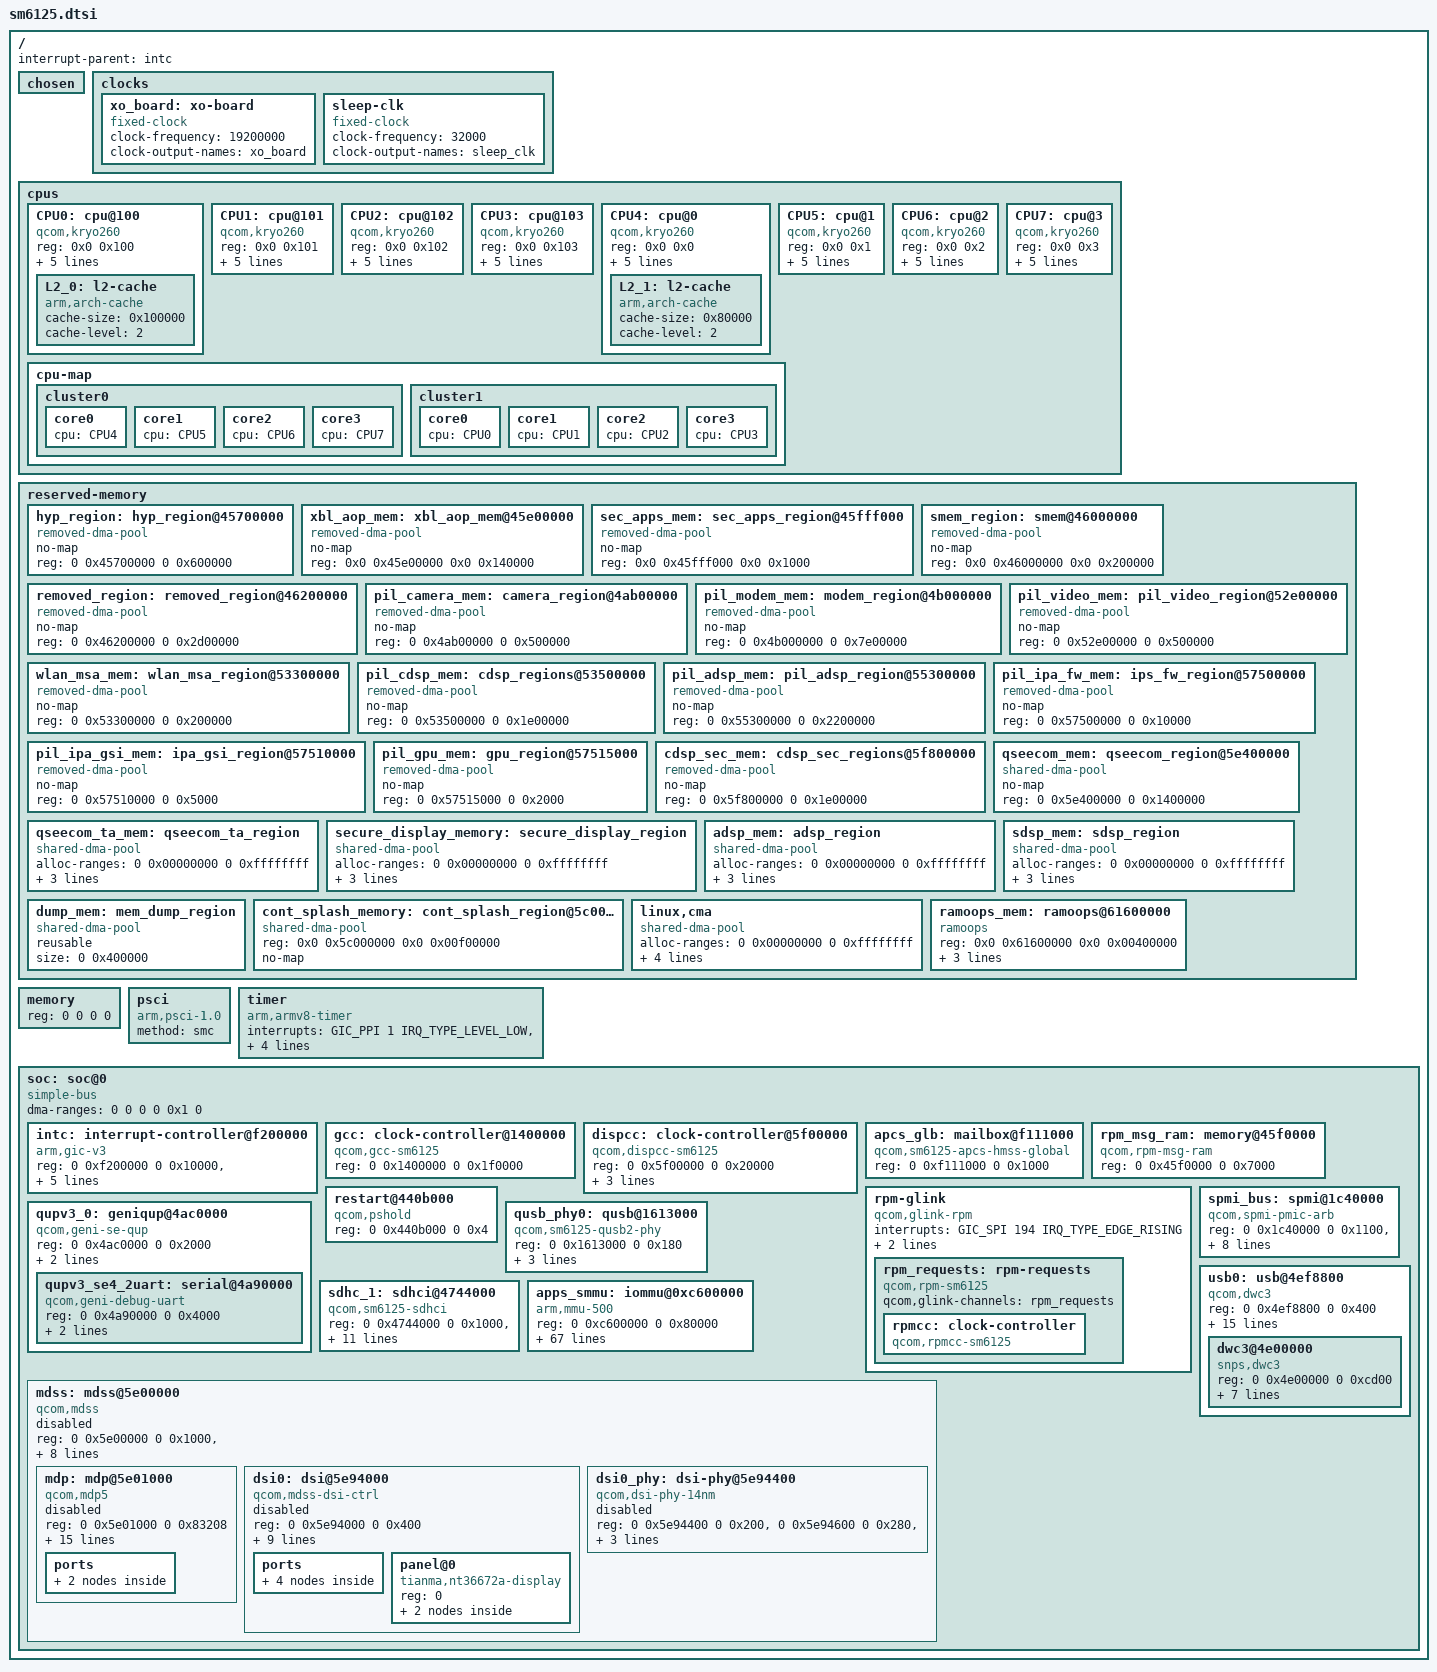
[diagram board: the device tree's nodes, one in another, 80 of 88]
// SPDX-License-Identifier: GPL-2.0-only
// Copyright (c) 2018-2019, The Linux Foundation. All rights reserved.
// Copyright (C) 2019 XiaoMi, Inc.
// Copyright (C) 2020 Eli Riggs <eli@rje.li>

#include <dt-bindings/interrupt-controller/arm-gic.h>
#include <dt-bindings/clock/qcom,gcc-sm6125.h>
#include <dt-bindings/clock/qcom,dispcc-sm6125.h>
#include <dt-bindings/clock/qcom,rpmcc.h>

/ {
	interrupt-parent = <&intc>;

	#address-cells = <2>;
	#size-cells = <2>;

	chosen { };

	clocks {
		xo_board: xo-board {
			compatible = "fixed-clock";
			#clock-cells = <0>;
			clock-frequency = <19200000>;
			clock-output-names = "xo_board";
		};
		sleep-clk {
			compatible = "fixed-clock";
			#clock-cells = <0>;
			clock-frequency = <32000>;
			clock-output-names = "sleep_clk";
		};
	};

	cpus {
		#address-cells = <2>;
		#size-cells = <0>;
		CPU0: cpu@100 {
			device_type = "cpu";
			compatible = "qcom,kryo260";
			reg = <0x0 0x100>;
			enable-method = "psci";
			capacity-dmips-mhz = <1638>;
			d-cache-size = <0x10000>;
			i-cache-size = <0x10000>;
			next-level-cache = <&L2_0>;
			#cooling-cells = <2>;
			L2_0: l2-cache {
				compatible = "arm,arch-cache";
				cache-size = <0x100000>;
				cache-level = <2>;
			};
		};
		CPU1: cpu@101 {
			device_type = "cpu";
			compatible = "qcom,kryo260";
			reg = <0x0 0x101>;
			enable-method = "psci";
			capacity-dmips-mhz = <1638>;
			d-cache-size = <0x10000>;
			i-cache-size = <0x10000>;
			next-level-cache = <&L2_0>;
			#cooling-cells = <2>;
		};
		CPU2: cpu@102 {
			device_type = "cpu";
			compatible = "qcom,kryo260";
			reg = <0x0 0x102>;
			enable-method = "psci";
			capacity-dmips-mhz = <1638>;
			d-cache-size = <0x10000>;
			i-cache-size = <0x10000>;
			next-level-cache = <&L2_0>;
			#cooling-cells = <2>;
		};
		CPU3: cpu@103 {
			device_type = "cpu";
			compatible = "qcom,kryo260";
			reg = <0x0 0x103>;
			enable-method = "psci";
			capacity-dmips-mhz = <1638>;
			d-cache-size = <0x10000>;
			i-cache-size = <0x10000>;
			next-level-cache = <&L2_0>;
			#cooling-cells = <2>;
		};
		CPU4: cpu@0 {
			device_type = "cpu";
			compatible = "qcom,kryo260";
			reg = <0x0 0x0>;
			enable-method = "psci";
			capacity-dmips-mhz = <1024>;
			d-cache-size = <0x8000>;
			i-cache-size = <0x8000>;
			next-level-cache = <&L2_1>;
			#cooling-cells = <2>;
			L2_1: l2-cache {
				compatible = "arm,arch-cache";
				cache-size = <0x80000>;
				cache-level = <2>;
			};
		};
		CPU5: cpu@1 {
			device_type = "cpu";
			compatible = "qcom,kryo260";
			reg = <0x0 0x1>;
			enable-method = "psci";
			capacity-dmips-mhz = <1024>;
			d-cache-size = <0x8000>;
			i-cache-size = <0x8000>;
			next-level-cache = <&L2_1>;
			#cooling-cells = <2>;
		};
		CPU6: cpu@2 {
			device_type = "cpu";
			compatible = "qcom,kryo260";
			reg = <0x0 0x2>;
			enable-method = "psci";
			capacity-dmips-mhz = <1024>;
			d-cache-size = <0x8000>;
			i-cache-size = <0x8000>;
			next-level-cache = <&L2_1>;
			#cooling-cells = <2>;
		};
		CPU7: cpu@3 {
			device_type = "cpu";
			compatible = "qcom,kryo260";
			reg = <0x0 0x3>;
			enable-method = "psci";
			capacity-dmips-mhz = <1024>;
			d-cache-size = <0x8000>;
			i-cache-size = <0x8000>;
			next-level-cache = <&L2_1>;
			#cooling-cells = <2>;
		};
		cpu-map {
			cluster0 {
				core0 {
					cpu = <&CPU4>;
				};
				core1 {
					cpu = <&CPU5>;
				};
				core2 {
					cpu = <&CPU6>;
				};
				core3 {
					cpu = <&CPU7>;
				};
			};
			cluster1 {
				core0 {
					cpu = <&CPU0>;
				};
				core1 {
					cpu = <&CPU1>;
				};
				core2 {
					cpu = <&CPU2>;
				};
				core3 {
					cpu = <&CPU3>;
				};
			};
		};
	};

	reserved-memory {
		#address-cells = <2>;
		#size-cells = <2>;
		ranges;

		hyp_region: hyp_region@45700000 {
			compatible = "removed-dma-pool";
			no-map;
			reg = <0 0x45700000 0 0x600000>;
		};

		xbl_aop_mem: xbl_aop_mem@45e00000 {
			compatible = "removed-dma-pool";
			no-map;
			reg = <0x0 0x45e00000 0x0 0x140000>;
		};

		sec_apps_mem: sec_apps_region@45fff000 {
			compatible = "removed-dma-pool";
			no-map;
			reg = <0x0 0x45fff000 0x0 0x1000>;
		};

		smem_region: smem@46000000 {
			compatible = "removed-dma-pool";
			no-map;
			reg = <0x0 0x46000000 0x0 0x200000>;
		};

		removed_region: removed_region@46200000 {
			compatible = "removed-dma-pool";
			no-map;
			reg = <0 0x46200000 0 0x2d00000>;
		};

		pil_camera_mem: camera_region@4ab00000 {
			compatible = "removed-dma-pool";
			no-map;
			reg = <0 0x4ab00000 0 0x500000>;
		};

		pil_modem_mem: modem_region@4b000000 {
			compatible = "removed-dma-pool";
			no-map;
			reg = <0 0x4b000000 0 0x7e00000>;
		};

		pil_video_mem: pil_video_region@52e00000 {
			compatible = "removed-dma-pool";
			no-map;
			reg = <0 0x52e00000 0 0x500000>;
		};

		wlan_msa_mem: wlan_msa_region@53300000 {
			compatible = "removed-dma-pool";
			no-map;
			reg = <0 0x53300000 0 0x200000>;
		};

		pil_cdsp_mem: cdsp_regions@53500000 {
			compatible = "removed-dma-pool";
			no-map;
			reg = <0 0x53500000 0 0x1e00000>;
		};

		pil_adsp_mem: pil_adsp_region@55300000 {
			compatible = "removed-dma-pool";
			no-map;
			reg = <0 0x55300000 0 0x2200000>;
		};

		pil_ipa_fw_mem: ips_fw_region@57500000 {
			compatible = "removed-dma-pool";
			no-map;
			reg = <0 0x57500000 0 0x10000>;
		};

		pil_ipa_gsi_mem: ipa_gsi_region@57510000 {
			compatible = "removed-dma-pool";
			no-map;
			reg = <0 0x57510000 0 0x5000>;
		};

		pil_gpu_mem: gpu_region@57515000 {
			compatible = "removed-dma-pool";
			no-map;
			reg = <0 0x57515000 0 0x2000>;
		};

		cdsp_sec_mem: cdsp_sec_regions@5f800000 {
			compatible = "removed-dma-pool";
			no-map;
			reg = <0 0x5f800000 0 0x1e00000>;
		};

		qseecom_mem: qseecom_region@5e400000 {
			compatible = "shared-dma-pool";
			no-map;
			reg = <0 0x5e400000 0 0x1400000>;
		};

		qseecom_ta_mem: qseecom_ta_region {
			compatible = "shared-dma-pool";
			alloc-ranges = <0 0x00000000 0 0xffffffff>;
			reusable;
			alignment = <0 0x400000>;
			size = <0 0x1000000>;
		};

		secure_display_memory: secure_display_region {
			compatible = "shared-dma-pool";
			alloc-ranges = <0 0x00000000 0 0xffffffff>;
			reusable;
			alignment = <0 0x400000>;
			size = <0 0x8c00000>;
		};

		adsp_mem: adsp_region {
			compatible = "shared-dma-pool";
			alloc-ranges = <0 0x00000000 0 0xffffffff>;
			reusable;
			alignment = <0 0x400000>;
			size = <0 0x800000>;
		};

		sdsp_mem: sdsp_region {
			compatible = "shared-dma-pool";
			alloc-ranges = <0 0x00000000 0 0xffffffff>;
			reusable;
			alignment = <0 0x400000>;
			size = <0 0x400000>;
		};

		dump_mem: mem_dump_region {
			compatible = "shared-dma-pool";
			reusable;
			size = <0 0x400000>;
		};


		cont_splash_memory: cont_splash_region@5c000000 {
			// reg = <0x0 0x5c000000 0x0 0x00f00000>;
			// label = "cont_splash_region";
			compatible = "shared-dma-pool";
			reg = <0x0 0x5c000000 0x0 0x00f00000>;
			no-map;
		};

		/*
		dfps_data_memory: dfps_data_region@5cf00000 {
			reg = <0x0 0x5cf00000 0x0 0x0100000>;
			label = "dfps_data_region";
		};
		*/

		/*
		disp_rdump_memory: disp_rdump_region@5c000000 {
			reg = <0x0 0x5c000000 0x0 0x01000000>;
			label = "disp_rdump_region";
		};
		*/

		/* global autoconfigured region for contiguous allocations */
		linux,cma {
			compatible = "shared-dma-pool";
			alloc-ranges = <0 0x00000000 0 0xffffffff>;
			reusable;
			alignment = <0 0x400000>;
			size = <0 0x2000000>;
			linux,cma-default;
		};

		/* reserve for pstore */
		ramoops_mem: ramoops@61600000 {
			compatible = "ramoops";
			reg = <0x0 0x61600000 0x0 0x00400000>;

			record-size = <0x80000>;
			pmsg-size = <0x200000>;
			console-size = <0x100000>;
		};
	};

	memory {
		device_type = "memory";
		/* We expect the bootloader to fill this in */
		reg = <0 0 0 0>;
	};

	psci {
		compatible = "arm,psci-1.0";
		method = "smc";
	};

	timer {
		compatible = "arm,armv8-timer";
		interrupts = <GIC_PPI 1 IRQ_TYPE_LEVEL_LOW>,
			     <GIC_PPI 2 IRQ_TYPE_LEVEL_LOW>,
			     <GIC_PPI 3 IRQ_TYPE_LEVEL_LOW>,
			     <GIC_PPI 0 IRQ_TYPE_LEVEL_LOW>;
		clock-frequency = <19200000>;
	};

	soc: soc@0 {
		#address-cells = <2>;
		#size-cells = <2>;
		ranges = <0 0 0 0 0x1 0>;
		dma-ranges = <0 0 0 0 0x1 0>;
		compatible = "simple-bus";

		intc: interrupt-controller@f200000 {
			compatible = "arm,gic-v3";
			reg = <0 0xf200000 0 0x10000>,	/* GICD */
			      <0 0xf300000 0 0x100000>;	/* GICR * 8 */
			#interrupt-cells = <3>;
			#address-cells = <2>;
			#size-cells = <2>;
			ranges;
			interrupt-controller;
			#redistributor-regions = <1>;
			redistributor-stride = <0x0 0x20000>;
			interrupts = <GIC_PPI 9 IRQ_TYPE_LEVEL_HIGH>;
		};

		gcc: clock-controller@1400000 {
			compatible = "qcom,gcc-sm6125";
			reg = <0 0x1400000 0 0x1f0000>;
			#clock-cells = <1>;
			#reset-cells = <1>;
			#power-domain-cells = <1>;
		};

		dispcc: clock-controller@5f00000 {
			compatible = "qcom,dispcc-sm6125";
			reg = <0 0x5f00000 0 0x20000>;

			clock-names = "bi_tcxo",
				      "gcc_disp_gpll0_div_clk_src",
				      "dsi0_phy_pll_out_byteclk",
				      "dsi0_phy_pll_out_dsiclk";
			clocks = <&rpmcc RPM_SMD_XO_CLK_SRC>,
				 <&gcc GCC_DISP_GPLL0_DIV_CLK_SRC>,
				 <&dsi0_phy 0>,
				 <&dsi0_phy 1>;

			#clock-cells = <1>;
			#power-domain-cells = <1>;
		};

		apcs_glb: mailbox@f111000 {
			compatible = "qcom,sm6125-apcs-hmss-global";
			reg = <0 0xf111000 0 0x1000>;
			#mbox-cells = <1>;
		};

		rpm_msg_ram: memory@45f0000 {
			compatible = "qcom,rpm-msg-ram";
			reg = <0 0x45f0000 0 0x7000>;
		};

		rpm-glink {
			compatible = "qcom,glink-rpm";
			interrupts = <GIC_SPI 194 IRQ_TYPE_EDGE_RISING>;
			qcom,rpm-msg-ram = <&rpm_msg_ram>;
			mboxes = <&apcs_glb 0>;
			rpm_requests: rpm-requests {
				compatible = "qcom,rpm-sm6125";
				qcom,glink-channels = "rpm_requests";
				rpmcc: clock-controller {
					compatible = "qcom,rpmcc-sm6125", "qcom,rpmcc";
					#clock-cells = <1>;
				};
			};
		};

		restart@440b000 {
			compatible = "qcom,pshold";
			reg = <0 0x440b000 0 0x4>;
		};

		spmi_bus: spmi@1c40000 {
			compatible = "qcom,spmi-pmic-arb";
			reg-names = "core", "chnls", "obsrvr", "intr", "cnfg";
			reg = <0 0x1c40000 0 0x1100>,
			      <0 0x1e00000 0 0x2000000>,
			      <0 0x3e00000 0 0x100000>,
			      <0 0x3f00000 0 0xa0000>,
			      <0 0x1c0a000 0 0x26000>;
			interrupt-names = "periph_irq";
			interrupts = <GIC_SPI 183 IRQ_TYPE_LEVEL_HIGH>;
			qcom,ee = <0>;
			qcom,channel = <0>;
			#address-cells = <2>;
			#size-cells = <0>;
			interrupt-controller;
			#interrupt-cells = <4>;
			cell-index = <0>;
		};

		qupv3_0: geniqup@4ac0000 {
			compatible = "qcom,geni-se-qup";
			reg = <0 0x4ac0000 0 0x2000>;
			clock-names = "m-ahb", "s-ahb";
			clocks = <&gcc GCC_QUPV3_WRAP_0_M_AHB_CLK>,
				 <&gcc GCC_QUPV3_WRAP_0_S_AHB_CLK>;
			#address-cells = <2>;
			#size-cells = <2>;
			ranges;

			qupv3_se4_2uart: serial@4a90000 {
				compatible = "qcom,geni-debug-uart";
				reg = <0 0x4a90000 0 0x4000>;
				interrupts = <GIC_SPI 331 IRQ_TYPE_LEVEL_HIGH>;
				clock-names = "se";
				clocks = <&gcc GCC_QUPV3_WRAP0_S4_CLK>;
			};
		};

		qusb_phy0: qusb@1613000 {
			compatible = "qcom,sm6125-qusb2-phy";
			reg = <0 0x1613000 0 0x180>;
			#phy-cells = <0>;

			clock-names = "cfg_ahb", "ref";
			clocks = <&gcc GCC_AHB2PHY_USB_CLK>,
				 <&rpmcc RPM_SMD_XO_CLK_SRC>;

			/*
			vdda-pll-supply = <&pm6125_l10>;
			vdda-phy-dpdm-supply = <&pm6125_l15>;
			*/

			resets = <&gcc GCC_QUSB2PHY_PRIM_BCR>;
		};

		usb0: usb@4ef8800 {
			compatible = "qcom,dwc3";
			reg = <0 0x4ef8800 0 0x400>;
			#address-cells = <2>;
			#size-cells = <2>;
			ranges;

			interrupt-names = "hs_phy_irq", "ss_phy_irq";
			interrupts = <GIC_SPI 260 IRQ_TYPE_LEVEL_HIGH>,
				     <GIC_SPI 422 IRQ_TYPE_LEVEL_HIGH>;

			clock-names = "core", "mock_utmi", "sleep",
				      "iface", "cfg_noc", "ref";
			clocks = <&gcc GCC_USB30_PRIM_MASTER_CLK>,
				 <&gcc GCC_USB30_PRIM_MOCK_UTMI_CLK>,
				 <&gcc GCC_USB30_PRIM_SLEEP_CLK>,
				 <&gcc GCC_SYS_NOC_USB3_PRIM_AXI_CLK>,
				 <&gcc GCC_CFG_NOC_USB3_PRIM_AXI_CLK>,
				 <&gcc GCC_USB3_PRIM_CLKREF_CLK>;

			assigned-clocks = <&gcc GCC_USB30_PRIM_MOCK_UTMI_CLK>,
					  <&gcc GCC_USB30_PRIM_MASTER_CLK>;
			assigned-clock-rates = <19200000>, <66666667>;

			reset-names = "core_reset";
			resets = <&gcc GCC_USB30_PRIM_BCR>;
			power-domains = <&gcc USB30_PRIM_GDSC>;

			qcom,select-utmi-as-pipe-clk;

			dwc3@4e00000 {
				compatible = "snps,dwc3";
				reg = <0 0x4e00000 0 0xcd00>;
				interrupts = <GIC_SPI 255 IRQ_TYPE_LEVEL_HIGH>;
				phy-names = "usb2-phy";
				phys = <&qusb_phy0>;
				snps,has-lpm-erratum;
				snps,hird-threshold = /bits/ 8 <0x10>;
				snps,usb3_lpm_capable;
				maximum-speed = "high-speed";
				dr_mode = "peripheral";
			};
		};

		sdhc_1: sdhci@4744000 {
			compatible = "qcom,sm6125-sdhci", "qcom,sdhci-msm-v5";
			reg-names = "hc", "cqhci";
			reg = <0 0x4744000 0 0x1000>,
			      <0 0x4745000 0 0x1000>;

			interrupt-names = "hc_irq", "pwr_irq";
			interrupts = <GIC_SPI 348 IRQ_TYPE_LEVEL_HIGH>,
				     <GIC_SPI 352 IRQ_TYPE_LEVEL_HIGH>;

			clock-names = "iface", "core";
			clocks = <&gcc GCC_SDCC1_AHB_CLK>,
				 <&gcc GCC_SDCC1_APPS_CLK>;

			bus-width = <8>;
			non-removable;
			supports-cqe;

			mmc-ddr-1_8v;
			mmc-hs200-1_8v;
			mmc-hs400-1_8v;
		};

		/*
		tlmm: pinctrl@400000 {
			compatible = "qcom,sm6125-pinctrl";
			reg = <0 0x400000 0 0xc00000>;
			interrupts = <GIC_SPI 227 IRQ_TYPE_LEVEL_HIGH>;
			gpio-controller;
			#gpio-cells = <2>;
			interrupt-controller;
			#interrupt-cells = <2>;
		};
		*/

		apps_smmu: iommu@0xc600000 {
			compatible = "arm,mmu-500";
			reg = <0 0xc600000 0 0x80000>;
			// status = "disabled";
			qcom,skip-init;
			#iommu-cells = <2>;
			#global-interrupts = <1>;
			interrupts =	<GIC_SPI 81 IRQ_TYPE_LEVEL_HIGH>,
					<GIC_SPI 88 IRQ_TYPE_LEVEL_HIGH>,
					<GIC_SPI 89 IRQ_TYPE_LEVEL_HIGH>,
					<GIC_SPI 90 IRQ_TYPE_LEVEL_HIGH>,
					<GIC_SPI 91 IRQ_TYPE_LEVEL_HIGH>,
					<GIC_SPI 92 IRQ_TYPE_LEVEL_HIGH>,
					<GIC_SPI 93 IRQ_TYPE_LEVEL_HIGH>,
					<GIC_SPI 94 IRQ_TYPE_LEVEL_HIGH>,
					<GIC_SPI 95 IRQ_TYPE_LEVEL_HIGH>,
					<GIC_SPI 96 IRQ_TYPE_LEVEL_HIGH>,
					<GIC_SPI 97 IRQ_TYPE_LEVEL_HIGH>,
					<GIC_SPI 98 IRQ_TYPE_LEVEL_HIGH>,
					<GIC_SPI 99 IRQ_TYPE_LEVEL_HIGH>,
					<GIC_SPI 100 IRQ_TYPE_LEVEL_HIGH>,
					<GIC_SPI 101 IRQ_TYPE_LEVEL_HIGH>,
					<GIC_SPI 102 IRQ_TYPE_LEVEL_HIGH>,
					<GIC_SPI 103 IRQ_TYPE_LEVEL_HIGH>,
					<GIC_SPI 104 IRQ_TYPE_LEVEL_HIGH>,
					<GIC_SPI 105 IRQ_TYPE_LEVEL_HIGH>,
					<GIC_SPI 106 IRQ_TYPE_LEVEL_HIGH>,
					<GIC_SPI 107 IRQ_TYPE_LEVEL_HIGH>,
					<GIC_SPI 108 IRQ_TYPE_LEVEL_HIGH>,
					<GIC_SPI 109 IRQ_TYPE_LEVEL_HIGH>,
					<GIC_SPI 110 IRQ_TYPE_LEVEL_HIGH>,
					<GIC_SPI 111 IRQ_TYPE_LEVEL_HIGH>,
					<GIC_SPI 112 IRQ_TYPE_LEVEL_HIGH>,
					<GIC_SPI 113 IRQ_TYPE_LEVEL_HIGH>,
					<GIC_SPI 114 IRQ_TYPE_LEVEL_HIGH>,
					<GIC_SPI 115 IRQ_TYPE_LEVEL_HIGH>,
					<GIC_SPI 116 IRQ_TYPE_LEVEL_HIGH>,
					<GIC_SPI 117 IRQ_TYPE_LEVEL_HIGH>,
					<GIC_SPI 118 IRQ_TYPE_LEVEL_HIGH>,
					<GIC_SPI 119 IRQ_TYPE_LEVEL_HIGH>,
					<GIC_SPI 120 IRQ_TYPE_LEVEL_HIGH>,
					<GIC_SPI 121 IRQ_TYPE_LEVEL_HIGH>,
					<GIC_SPI 122 IRQ_TYPE_LEVEL_HIGH>,
					<GIC_SPI 123 IRQ_TYPE_LEVEL_HIGH>,
					<GIC_SPI 124 IRQ_TYPE_LEVEL_HIGH>,
					<GIC_SPI 125 IRQ_TYPE_LEVEL_HIGH>,
					<GIC_SPI 126 IRQ_TYPE_LEVEL_HIGH>,
					<GIC_SPI 127 IRQ_TYPE_LEVEL_HIGH>,
					<GIC_SPI 128 IRQ_TYPE_LEVEL_HIGH>,
					<GIC_SPI 129 IRQ_TYPE_LEVEL_HIGH>,
					<GIC_SPI 130 IRQ_TYPE_LEVEL_HIGH>,
					<GIC_SPI 131 IRQ_TYPE_LEVEL_HIGH>,
					<GIC_SPI 132 IRQ_TYPE_LEVEL_HIGH>,
					<GIC_SPI 133 IRQ_TYPE_LEVEL_HIGH>,
					<GIC_SPI 134 IRQ_TYPE_LEVEL_HIGH>,
					<GIC_SPI 135 IRQ_TYPE_LEVEL_HIGH>,
					<GIC_SPI 136 IRQ_TYPE_LEVEL_HIGH>,
					<GIC_SPI 137 IRQ_TYPE_LEVEL_HIGH>,
					<GIC_SPI 138 IRQ_TYPE_LEVEL_HIGH>,
					<GIC_SPI 139 IRQ_TYPE_LEVEL_HIGH>,
					<GIC_SPI 140 IRQ_TYPE_LEVEL_HIGH>,
					<GIC_SPI 141 IRQ_TYPE_LEVEL_HIGH>,
					<GIC_SPI 142 IRQ_TYPE_LEVEL_HIGH>,
					<GIC_SPI 143 IRQ_TYPE_LEVEL_HIGH>,
					<GIC_SPI 144 IRQ_TYPE_LEVEL_HIGH>,
					<GIC_SPI 145 IRQ_TYPE_LEVEL_HIGH>,
					<GIC_SPI 146 IRQ_TYPE_LEVEL_HIGH>,
					<GIC_SPI 147 IRQ_TYPE_LEVEL_HIGH>,
					<GIC_SPI 148 IRQ_TYPE_LEVEL_HIGH>,
					<GIC_SPI 149 IRQ_TYPE_LEVEL_HIGH>,
					<GIC_SPI 150 IRQ_TYPE_LEVEL_HIGH>,
					<GIC_SPI 151 IRQ_TYPE_LEVEL_HIGH>;
		};

		mdss: mdss@5e00000 {
			compatible = "qcom,mdss";
			reg-names = "mdss_phys", "vbif_phys";
			reg = <0 0x5e00000 0 0x1000>,
			      <0 0x5eb0000 0 0x2008>;

			power-domains = <&dispcc MDSS_CORE_GDSC>;

			clock-names = "iface", "bus", "ahb", "core";
			clocks = <&gcc GCC_DISP_AHB_CLK>,
				 <&gcc GCC_DISP_HF_AXI_CLK>,
				 <&dispcc DISP_CC_MDSS_AHB_CLK>,
				 <&dispcc DISP_CC_MDSS_MDP_CLK>;

			/*
			assigned-clocks = <&dispcc DISP_CC_MDSS_MDP_CLK>;
			assigned-clock-rates = <307000000>;
			*/

			interrupts = <GIC_SPI 186 IRQ_TYPE_LEVEL_HIGH>;
			interrupt-controller;
			#interrupt-cells = <1>;

			#address-cells = <2>;
			#size-cells = <2>;
			ranges;

			status = "disabled";

			/* memory-region = <&cont_splash_memory>; */

			mdp: mdp@5e01000 {
				compatible = "qcom,mdp5";
				reg-names = "mdp_phys";
				reg = <0 0x5e01000 0 0x83208>;

				interrupt-parent = <&mdss>;
				interrupts = <0 IRQ_TYPE_LEVEL_HIGH>;

				clock-names = "iface", "rot", "lut", "core", "vsync", "bus";
				clocks = <&dispcc DISP_CC_MDSS_AHB_CLK>,
					 <&dispcc DISP_CC_MDSS_ROT_CLK>,
					 <&dispcc DISP_CC_MDSS_MDP_LUT_CLK>,
					 <&dispcc DISP_CC_MDSS_MDP_CLK>,
					 <&dispcc DISP_CC_MDSS_VSYNC_CLK>,
					 <&gcc GCC_DISP_HF_AXI_CLK>;

				assigned-clocks = <&dispcc DISP_CC_MDSS_VSYNC_CLK>,
						  <&dispcc DISP_CC_MDSS_MDP_LUT_CLK>,
						  <&dispcc DISP_CC_MDSS_ROT_CLK>;
				assigned-clock-rates = <256000000>, <19200000>, <19200000>;

				iommus = <&apps_smmu 0x400 0>;

				status = "disabled";

				ports {
					#address-cells = <1>;
					#size-cells = <0>;

					port@0 {
						reg = <0>;
						mdp5_intf1_out: endpoint {
							remote-endpoint = <&dsi0_in>;
						};
					};
				};
			};

			dsi0: dsi@5e94000 {
				compatible = "qcom,mdss-dsi-ctrl";
				reg-names = "dsi_ctrl";
				reg = <0 0x5e94000 0 0x400>;

				interrupt-parent = <&mdss>;
				interrupts = <4 IRQ_TYPE_LEVEL_HIGH>;

				clock-names = "byte", "byte_intf", "pixel", "core", "iface", "bus";
				clocks = <&dispcc DISP_CC_MDSS_BYTE0_CLK>,
					 <&dispcc DISP_CC_MDSS_BYTE0_INTF_CLK>,
					 <&dispcc DISP_CC_MDSS_PCLK0_CLK>,
					 <&dispcc DISP_CC_MDSS_ESC0_CLK>,
					 <&dispcc DISP_CC_MDSS_AHB_CLK>,
					 <&gcc GCC_DISP_HF_AXI_CLK>;

				phy-names = "dsi";
				phys = <&dsi0_phy>;

				#address-cells = <1>;
				#size-cells = <0>;

				status = "disabled";

				ports {
					#address-cells = <1>;
					#size-cells = <0>;

					port@0 {
						reg = <0>;
						dsi0_in: endpoint {
							remote-endpoint = <&mdp5_intf1_out>;
						};
					};

					port@1 {
						reg = <1>;
						dsi0_out: endpoint {
							remote-endpoint = <&tianma_in>;
							data-lanes = <0 1 2 3>;
						};
					};
				};

				panel@0 {
					compatible = "tianma,nt36672a-display";
					reg = <0>;

					port {
						tianma_in: endpoint {
							remote-endpoint = <&dsi0_out>;
						};
					};
				};
			};

			dsi0_phy: dsi-phy@5e94400 {
				compatible = "qcom,dsi-phy-14nm";
				reg-names = "dsi_phy", "dsi_phy_lane", "dsi_pll";
				reg = <0 0x5e94400 0 0x200>,
				      <0 0x5e94600 0 0x280>,
				      <0 0x5e01400 0 0x1e0>;

				clock-names = "iface", "ref";
				clocks = <&dispcc DISP_CC_MDSS_AHB_CLK>,
					 <&rpmcc RPM_SMD_XO_CLK_SRC>;

				#clock-cells = <1>;
				#phy-cells = <0>;

				status = "disabled";
			};

		};

	};
};
